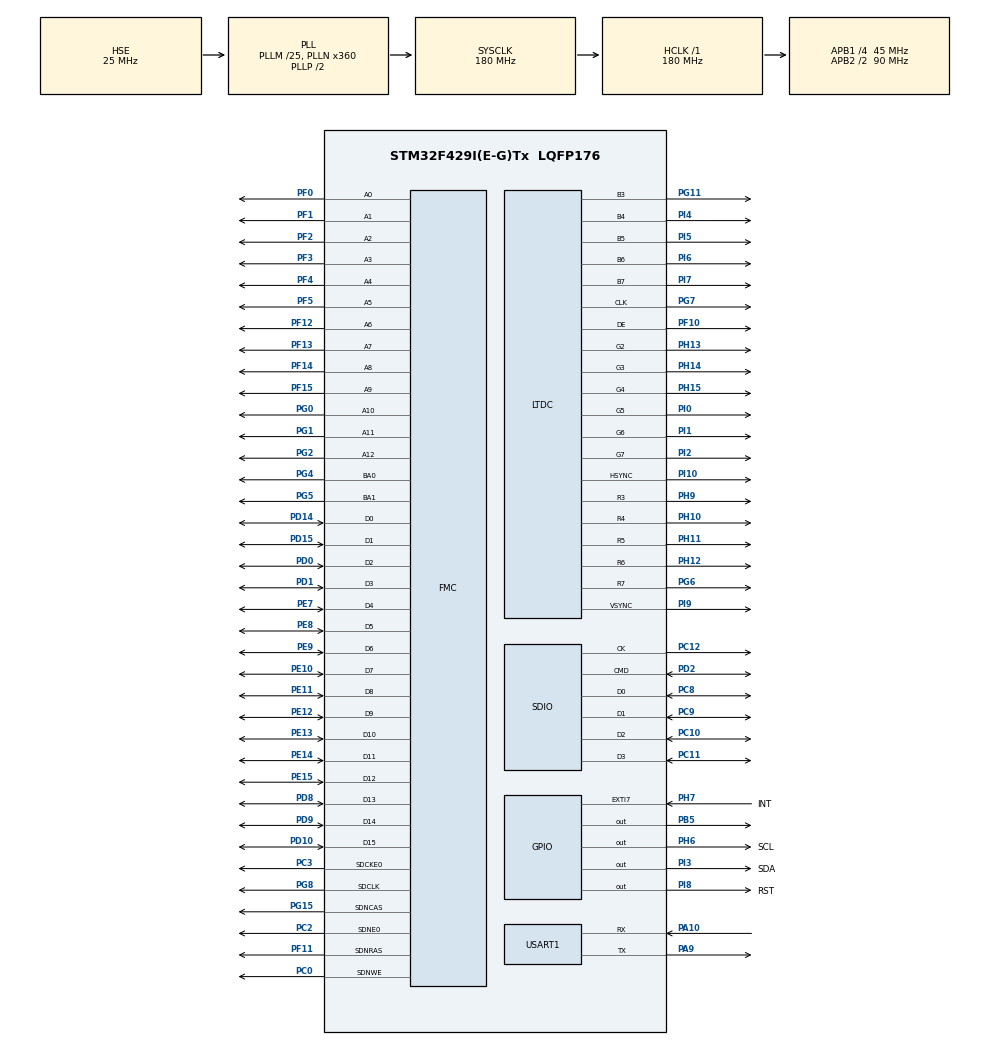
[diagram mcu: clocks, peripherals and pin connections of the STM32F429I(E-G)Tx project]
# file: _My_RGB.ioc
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DMA2D.ColorMode=DMA2D_OUTPUT_RGB565
Dma.Request0=SDIO_RX
Dma.Request1=SDIO_TX
Dma.SDIO_RX.0.Direction=DMA_PERIPH_TO_MEMORY
Dma.SDIO_RX.0.FIFOMode=DMA_FIFOMODE_ENABLE
Dma.SDIO_RX.0.FIFOThreshold=DMA_FIFO_THRESHOLD_FULL
Dma.SDIO_RX.0.Instance=DMA2_Stream3
Dma.SDIO_RX.0.MemBurst=DMA_MBURST_INC4
Dma.SDIO_RX.0.MemDataAlignment=DMA_MDATAALIGN_WORD
Dma.SDIO_RX.0.MemInc=DMA_MINC_ENABLE
Dma.SDIO_RX.0.Mode=DMA_PFCTRL
Dma.SDIO_RX.0.PeriphBurst=DMA_PBURST_INC4
Dma.SDIO_RX.0.PeriphDataAlignment=DMA_PDATAALIGN_WORD
Dma.SDIO_RX.0.PeriphInc=DMA_PINC_DISABLE
Dma.SDIO_RX.0.Priority=DMA_PRIORITY_LOW
Dma.SDIO_TX.1.Direction=DMA_MEMORY_TO_PERIPH
Dma.SDIO_TX.1.FIFOMode=DMA_FIFOMODE_ENABLE
Dma.SDIO_TX.1.FIFOThreshold=DMA_FIFO_THRESHOLD_FULL
Dma.SDIO_TX.1.Instance=DMA2_Stream6
Dma.SDIO_TX.1.MemBurst=DMA_MBURST_INC4
Dma.SDIO_TX.1.MemDataAlignment=DMA_MDATAALIGN_WORD
Dma.SDIO_TX.1.MemInc=DMA_MINC_ENABLE
Dma.SDIO_TX.1.Mode=DMA_PFCTRL
Dma.SDIO_TX.1.PeriphBurst=DMA_PBURST_INC4
Dma.SDIO_TX.1.PeriphDataAlignment=DMA_PDATAALIGN_WORD
Dma.SDIO_TX.1.PeriphInc=DMA_PINC_DISABLE
Dma.SDIO_TX.1.Priority=DMA_PRIORITY_LOW
FATFS._CODE_PAGE=936
FATFS._USE_LFN=2
FMC.CASLatency1=FMC_SDRAM_CAS_LATENCY_3
FMC.ColumnBitsNumber1=FMC_SDRAM_COLUMN_BITS_NUM_9
FMC.ExitSelfRefreshDelay1=8
FMC.LoadToActiveDelay1=2
FMC.RCDDelay1=2
FMC.RPDelay1=2
FMC.ReadPipeDelay1=FMC_SDRAM_RPIPE_DELAY_1
FMC.RowCycleDelay1=6
FMC.SDClockPeriod1=FMC_SDRAM_CLOCK_PERIOD_2
FMC.SelfRefreshTime1=6
FMC.WriteRecoveryTime1=4
LTDC.ActiveW=800
LTDC.Alpha_L0=255
LTDC.FBStartAdress_L0=0xC0000000
LTDC.FBStartAdress_L1=0xC0200000
LTDC.HBP=88
LTDC.HFP=40
LTDC.HSync=48
LTDC.ImageHeight_L0=480
LTDC.ImageHeight_L1=480
LTDC.ImageWidth_L0=800
LTDC.ImageWidth_L1=800
LTDC.PixelFormat_L0=LTDC_PIXEL_FORMAT_RGB565
LTDC.PixelFormat_L1=LTDC_PIXEL_FORMAT_RGB565
LTDC.VBP=32
LTDC.VFP=13
LTDC.VSPolarity=LTDC_VSPOLARITY_AL
LTDC.VSync=3
LTDC.WindowX1_L0=800
LTDC.WindowX1_L1=800
LTDC.WindowY1_L0=480
LTDC.WindowY1_L1=480
Mcu.Family=STM32F4
Mcu.Name=STM32F429I(E-G)Tx
Mcu.Package=LQFP176
NVIC.DMA2_Stream3_IRQn=true\:3\:3\:true\:false\:true\:false\:true
NVIC.DMA2_Stream6_IRQn=true\:3\:3\:true\:false\:true\:false\:true
NVIC.EXTI9_5_IRQn=true\:1\:1\:true\:false\:true\:true\:true
NVIC.PriorityGroup=NVIC_PRIORITYGROUP_2
NVIC.SDIO_IRQn=true\:0\:0\:false\:false\:true\:true\:true
NVIC.USART1_IRQn=true\:1\:1\:true\:false\:true\:true\:true
PA10.Mode=Asynchronous
PA10.Signal=USART1_RX
PA9.Mode=Asynchronous
PA9.Signal=USART1_TX
PB5.GPIO_PuPd=GPIO_PULLUP
PB5.GPIO_Speed=GPIO_SPEED_FREQ_VERY_HIGH
PB5.PinState=GPIO_PIN_SET
PB5.Signal=GPIO_Output
PC0.GPIO_PuPd=GPIO_PULLUP
PC0.Signal=FMC_SDNWE
PC10.Mode=SD_4_bits_Wide_bus
PC10.Signal=SDIO_D2
PC11.Mode=SD_4_bits_Wide_bus
PC11.Signal=SDIO_D3
PC12.Mode=SD_4_bits_Wide_bus
PC12.Signal=SDIO_CK
PC2.GPIO_PuPd=GPIO_PULLUP
PC2.Mode=SdramChipSelect1_1
PC2.Signal=FMC_SDNE0
PC3.GPIO_PuPd=GPIO_PULLUP
PC3.Mode=SdramChipSelect1_1
PC3.Signal=FMC_SDCKE0
PC8.Mode=SD_4_bits_Wide_bus
PC8.Signal=SDIO_D0
PC9.Mode=SD_4_bits_Wide_bus
PC9.Signal=SDIO_D1
PD0.GPIO_PuPd=GPIO_PULLUP
PD0.Signal=FMC_D2_DA2
PD1.GPIO_PuPd=GPIO_PULLUP
PD1.Signal=FMC_D3_DA3
PD10.GPIO_PuPd=GPIO_PULLUP
PD10.Signal=FMC_D15_DA15
PD14.GPIO_PuPd=GPIO_PULLUP
PD14.Signal=FMC_D0_DA0
PD15.GPIO_PuPd=GPIO_PULLUP
PD15.Signal=FMC_D1_DA1
PD2.Mode=SD_4_bits_Wide_bus
PD2.Signal=SDIO_CMD
PD8.GPIO_PuPd=GPIO_PULLUP
PD8.Signal=FMC_D13_DA13
PD9.GPIO_PuPd=GPIO_PULLUP
PD9.Signal=FMC_D14_DA14
PE0.Signal=FMC_NBL0
PE1.Signal=FMC_NBL1
PE10.GPIO_PuPd=GPIO_PULLUP
PE10.Signal=FMC_D7_DA7
PE11.GPIO_PuPd=GPIO_PULLUP
PE11.Signal=FMC_D8_DA8
PE12.GPIO_PuPd=GPIO_PULLUP
PE12.Signal=FMC_D9_DA9
PE13.GPIO_PuPd=GPIO_PULLUP
PE13.Signal=FMC_D10_DA10
PE14.GPIO_PuPd=GPIO_PULLUP
PE14.Signal=FMC_D11_DA11
PE15.GPIO_PuPd=GPIO_PULLUP
PE15.Signal=FMC_D12_DA12
PE7.GPIO_PuPd=GPIO_PULLUP
PE7.Signal=FMC_D4_DA4
PE8.GPIO_PuPd=GPIO_PULLUP
PE8.Signal=FMC_D5_DA5
PE9.GPIO_PuPd=GPIO_PULLUP
PE9.Signal=FMC_D6_DA6
PF0.GPIO_PuPd=GPIO_PULLUP
PF0.Signal=FMC_A0
PF1.GPIO_PuPd=GPIO_PULLUP
PF1.Signal=FMC_A1
PF10.GPIO_Speed=GPIO_SPEED_FREQ_VERY_HIGH
PF10.Mode=RGB565
PF10.Signal=LTDC_DE
PF11.GPIO_PuPd=GPIO_PULLUP
PF11.Signal=FMC_SDNRAS
PF12.GPIO_PuPd=GPIO_PULLUP
PF12.Signal=FMC_A6
PF13.GPIO_PuPd=GPIO_PULLUP
PF13.Signal=FMC_A7
PF14.GPIO_PuPd=GPIO_PULLUP
PF14.Signal=FMC_A8
PF15.GPIO_PuPd=GPIO_PULLUP
PF15.Signal=FMC_A9
PF2.GPIO_PuPd=GPIO_PULLUP
PF2.Signal=FMC_A2
PF3.GPIO_PuPd=GPIO_PULLUP
PF3.Signal=FMC_A3
PF4.GPIO_PuPd=GPIO_PULLUP
PF4.Signal=FMC_A4
PF5.GPIO_PuPd=GPIO_PULLUP
PF5.Signal=FMC_A5
PG0.GPIO_PuPd=GPIO_PULLUP
PG0.Signal=FMC_A10
PG1.GPIO_PuPd=GPIO_PULLUP
PG1.Signal=FMC_A11
PG11.GPIO_Speed=GPIO_SPEED_FREQ_VERY_HIGH
PG11.Mode=RGB565
PG11.Signal=LTDC_B3
PG15.GPIO_PuPd=GPIO_PULLUP
PG15.Signal=FMC_SDNCAS
PG2.GPIO_PuPd=GPIO_PULLUP
PG2.Signal=FMC_A12
PG4.GPIO_PuPd=GPIO_PULLUP
PG4.Signal=FMC_A14_BA0
PG5.GPIO_PuPd=GPIO_PULLUP
PG5.Signal=FMC_A15_BA1
PG6.GPIO_Speed=GPIO_SPEED_FREQ_VERY_HIGH
PG6.Mode=RGB565
PG6.Signal=LTDC_R7
PG7.GPIO_Speed=GPIO_SPEED_FREQ_VERY_HIGH
PG7.Mode=RGB565
PG7.Signal=LTDC_CLK
PG8.GPIO_PuPd=GPIO_PULLUP
PG8.Signal=FMC_SDCLK
PH0/OSC_IN.Mode=HSE-External-Oscillator
PH0/OSC_IN.Signal=RCC_OSC_IN
PH1/OSC_OUT.Mode=HSE-External-Oscillator
PH1/OSC_OUT.Signal=RCC_OSC_OUT
PH10.GPIO_Speed=GPIO_SPEED_FREQ_VERY_HIGH
PH10.Mode=RGB565
PH10.Signal=LTDC_R4
PH11.GPIO_Speed=GPIO_SPEED_FREQ_VERY_HIGH
PH11.Mode=RGB565
PH11.Signal=LTDC_R5
PH12.GPIO_Speed=GPIO_SPEED_FREQ_VERY_HIGH
PH12.Mode=RGB565
PH12.Signal=LTDC_R6
PH13.GPIO_Speed=GPIO_SPEED_FREQ_VERY_HIGH
PH13.Mode=RGB565
PH13.Signal=LTDC_G2
PH14.GPIO_Speed=GPIO_SPEED_FREQ_VERY_HIGH
PH14.Mode=RGB565
PH14.Signal=LTDC_G3
PH15.GPIO_Speed=GPIO_SPEED_FREQ_VERY_HIGH
PH15.Mode=RGB565
PH15.Signal=LTDC_G4
PH6.GPIO_Label=SCL
PH6.GPIO_Speed=GPIO_SPEED_FREQ_VERY_HIGH
PH6.Signal=GPIO_Output
PH7.GPIO_Label=INT
PH7.GPIO_ModeDefaultEXTI=GPIO_MODE_IT_FALLING
PH7.GPIO_PuPd=GPIO_PULLUP
PH7.Signal=GPXTI7
PH9.GPIO_Speed=GPIO_SPEED_FREQ_VERY_HIGH
PH9.Mode=RGB565
PH9.Signal=LTDC_R3
PI0.GPIO_Speed=GPIO_SPEED_FREQ_VERY_HIGH
PI0.Mode=RGB565
PI0.Signal=LTDC_G5
PI1.GPIO_Speed=GPIO_SPEED_FREQ_VERY_HIGH
PI1.Mode=RGB565
PI1.Signal=LTDC_G6
PI10.GPIO_Speed=GPIO_SPEED_FREQ_VERY_HIGH
PI10.Mode=RGB565
PI10.Signal=LTDC_HSYNC
PI2.GPIO_Speed=GPIO_SPEED_FREQ_VERY_HIGH
PI2.Mode=RGB565
PI2.Signal=LTDC_G7
PI3.GPIO_Label=SDA
PI3.GPIO_Speed=GPIO_SPEED_FREQ_VERY_HIGH
PI3.Signal=GPIO_Output
PI4.GPIO_Speed=GPIO_SPEED_FREQ_VERY_HIGH
PI4.Mode=RGB565
PI4.Signal=LTDC_B4
PI5.GPIO_Speed=GPIO_SPEED_FREQ_VERY_HIGH
PI5.Mode=RGB565
PI5.Signal=LTDC_B5
PI6.GPIO_Speed=GPIO_SPEED_FREQ_VERY_HIGH
PI6.Mode=RGB565
PI6.Signal=LTDC_B6
PI7.GPIO_Speed=GPIO_SPEED_FREQ_VERY_HIGH
PI7.Mode=RGB565
PI7.Signal=LTDC_B7
PI8.GPIO_Label=RST
PI8.Signal=GPIO_Output
PI9.GPIO_Speed=GPIO_SPEED_FREQ_VERY_HIGH
PI9.Mode=RGB565
PI9.Signal=LTDC_VSYNC
ProjectManager.HeapSize=0x1000
ProjectManager.StackSize=0x1000
ProjectManager.TargetToolchain=MDK-ARM V5.27
RCC.48MHZClocksFreq_Value=45000000
RCC.AHBFreq_Value=180000000
RCC.APB1CLKDivider=RCC_HCLK_DIV4
RCC.APB1Freq_Value=45000000
RCC.APB1TimFreq_Value=90000000
RCC.APB2CLKDivider=RCC_HCLK_DIV2
RCC.APB2Freq_Value=90000000
RCC.APB2TimFreq_Value=180000000
RCC.CortexFreq_Value=180000000
RCC.HCLKFreq_Value=180000000
RCC.HSE_VALUE=25000000
RCC.HSI_VALUE=16000000
RCC.LSE_VALUE=32768
RCC.PLLM=25
RCC.PLLN=360
RCC.PLLQ=8
RCC.PLLSAIN=152
RCC.PLLSourceVirtual=RCC_PLLSOURCE_HSE
RCC.SYSCLKFreq_VALUE=180000000
RCC.SYSCLKSource=RCC_SYSCLKSOURCE_PLLCLK
RCC.VCOOutputFreq_Value=360000000
SDIO.ClockDiv=4
SH.FMC_A0.0=FMC_A0,13b-sda1
SH.FMC_A1.0=FMC_A1,13b-sda1
SH.FMC_A10.0=FMC_A10,13b-sda1
SH.FMC_A11.0=FMC_A11,13b-sda1
SH.FMC_A12.0=FMC_A12,13b-sda1
SH.FMC_A14_BA0.0=FMC_BA0,FourSdramBanks1
SH.FMC_A15_BA1.0=FMC_BA1,FourSdramBanks1
SH.FMC_A2.0=FMC_A2,13b-sda1
SH.FMC_A3.0=FMC_A3,13b-sda1
SH.FMC_A4.0=FMC_A4,13b-sda1
SH.FMC_A5.0=FMC_A5,13b-sda1
SH.FMC_A6.0=FMC_A6,13b-sda1
SH.FMC_A7.0=FMC_A7,13b-sda1
SH.FMC_A8.0=FMC_A8,13b-sda1
SH.FMC_A9.0=FMC_A9,13b-sda1
SH.FMC_D0_DA0.0=FMC_D0,sd-16b-d1
SH.FMC_D10_DA10.0=FMC_D10,sd-16b-d1
SH.FMC_D11_DA11.0=FMC_D11,sd-16b-d1
SH.FMC_D12_DA12.0=FMC_D12,sd-16b-d1
SH.FMC_D13_DA13.0=FMC_D13,sd-16b-d1
SH.FMC_D14_DA14.0=FMC_D14,sd-16b-d1
SH.FMC_D15_DA15.0=FMC_D15,sd-16b-d1
SH.FMC_D1_DA1.0=FMC_D1,sd-16b-d1
SH.FMC_D2_DA2.0=FMC_D2,sd-16b-d1
SH.FMC_D3_DA3.0=FMC_D3,sd-16b-d1
SH.FMC_D4_DA4.0=FMC_D4,sd-16b-d1
SH.FMC_D5_DA5.0=FMC_D5,sd-16b-d1
SH.FMC_D6_DA6.0=FMC_D6,sd-16b-d1
SH.FMC_D7_DA7.0=FMC_D7,sd-16b-d1
SH.FMC_D8_DA8.0=FMC_D8,sd-16b-d1
SH.FMC_D9_DA9.0=FMC_D9,sd-16b-d1
SH.FMC_NBL0.0=FMC_NBL0
SH.FMC_NBL1.0=FMC_NBL1
SH.FMC_SDCLK.0=FMC_SDCLK,13b-sda1
SH.FMC_SDNCAS.0=FMC_SDNCAS,13b-sda1
SH.FMC_SDNRAS.0=FMC_SDNRAS,13b-sda1
SH.FMC_SDNWE.0=FMC_SDNWE,13b-sda1
USART1.VirtualMode=VM_ASYNC
VP_DMA2D_VS_DMA2D.Mode=DMA2D_Activate
VP_FATFS_VS_SDIO.Mode=SDIO
board=custom

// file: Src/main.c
/* USER CODE BEGIN Header */
/**
  ******************************************************************************
  * @file           : main.c
  * @brief          : Main program body
  ******************************************************************************
  * @attention
  *
  * <h2><center>&copy; Copyright (c) 2020 STMicroelectronics.
  * All rights reserved.</center></h2>
  *
  * This software component is licensed by ST under BSD 3-Clause license,
  * the "License"; You may not use this file except in compliance with the
  * License. You may obtain a copy of the License at:
  *                        opensource.org/licenses/BSD-3-Clause
  *
  ******************************************************************************
  */
/* USER CODE END Header */

#include "main.h"
#include "dma.h"
#include "dma2d.h"
#include "fatfs.h"
#include "ltdc.h"
#include "sdio.h"
#include "usart.h"
#include "gpio.h"
#include "fmc.h"

/* USER CODE BEGIN Includes */

#include "BSP_RGB_LCD.h"
#include "image.h"
#include "GUI_Paint.h"
#include "GT911.h"
#include "malloc.h"
#include "usmart.h"
#include "ff.h"
#include "ff_gen_drv.h"
#include "piclib.h"

/* USER CODE END Includes */

/* USER CODE BEGIN PTD */
extern GT911_Dev Dev_Now;

void HAL_GPIO_EXTI_Callback(uint16_t GPIO_Pin)
{
	if(GPIO_Pin == GPIO_PIN_7)
	{
		Dev_Now.Touch = 1;
	}
}
/* USER CODE END PTD */

void SystemClock_Config(void);

/* USER CODE BEGIN 0 */

//FATFS SDFatFs;  /* File system object for SD card logical drive */
//FIL MyFile;     /* File object */
//char SDPath[4]; /* SD card logical drive path */
//static uint8_t buffer[_MAX_SS]; /* a work buffer for the f_mkfs() */

uint16_t *picture = NULL;

/* USER CODE END 0 */

int main(void)
{
  /* USER CODE BEGIN 1 */

//  FRESULT res;                                          /* FatFs function common result code */
//  uint32_t byteswritten, bytesread;                     /* File write/read counts */
//  uint8_t wtext[] = "This is STM32 working with FatFs"; /* File write buffer */
//  uint8_t rtext[100];                                   /* File read buffer */
//	uint8_t buffer[512];

  /* USER CODE END 1 */

  /* MCU Configuration--------------------------------------------------------*/

  /* Reset of all peripherals, Initializes the Flash interface and the Systick. */
  HAL_Init();

  /* Configure the system clock */
  SystemClock_Config();

  /* Initialize all configured peripherals */
  MX_GPIO_Init();
  MX_LTDC_Init();
  MX_FMC_Init();
  MX_DMA2D_Init();
  MX_USART1_UART_Init();
  MX_DMA_Init();
  MX_SDIO_SD_Init();
//  MX_FATFS_Init();
  /* USER CODE BEGIN 2 */

	/*LCD初始化*/
	BSP_LCD_Init();

	/*打开背光*/
	HAL_GPIO_WritePin(GPIOB,GPIO_PIN_5,GPIO_PIN_SET);

/*malloc.c中初始化内存池*/
	my_mem_init(SRAMIN);		    //初始化内部内存池
	my_mem_init(SRAMEX);		    //初始化外部内存池
	my_mem_init(SRAMCCM);		    //初始化CCM内存池

/*USMART调试工具初始化*/
	usmart_dev.init(90);

	/*使能串口1接受中断*/
	__HAL_UART_ENABLE_IT(&huart1,UART_IT_RXNE);

	/*为fatfs相关变量申请内存	*/
	exfuns_init();

	/*FATFS文件系统初始化，初始化SD卡并挂载SD卡*/
	if(FATFS_LinkDriver(&SD_Driver, SDPath) == 0)
		{
			/*##-2- Register the file system object to the FatFs module ##############*/
			if(f_mount(&SDFatFS, (TCHAR const*)SDPath, 0) != FR_OK)
			{
				/* FatFs Initialization Error */
				Error_Handler();
				Debug("挂载失败\r\n");
			}
			else
			{
				/*##-3- Create a FAT file system (format) on the logical drive #########*/
				/* WARNING: Formatting the uSD card will delete all content on the device */
				if(disk_initialize(0) != 0)//在这一步进行了SD卡初始化   f_mkfs((TCHAR const*)SDPath, FM_ANY, 0, buffer, sizeof(buffer)) != FR_OK  disk_initialize(0) != 0
				{
					/* FatFs Format Error */
					Error_Handler();
					Debug("SD卡初始化失败\r\n");
				}
				else
				{
					/*##-4- Create and Open a new text file object with write access #####*/
//					if(f_open(&SDFile, "STM32.TXT", FA_CREATE_ALWAYS | FA_WRITE) != FR_OK)
//					{
//						/* 'STM32.TXT' file Open for write Error */
//						Error_Handler();
//						Debug("创建文件失败\r\n");
//					}
//					else
//					{
//						/*##-5- Write data to the text file ################################*/
//						res = f_write(&SDFile, wtext, sizeof(wtext), (void *)&byteswritten);

//						/*##-6- Close the open text file #################################*/
//						if (f_close(&SDFile) != FR_OK )
//						{
//							Error_Handler();
//							Debug("关闭文件失败\r\n");
//						}
//
//						if((byteswritten == 0) || (res != FR_OK))
//						{
//							/* 'STM32.TXT' file Write or EOF Error */
//							Error_Handler();
//							Debug("写文件信息失败\r\n");
//						}
//						else
//						{
//							/*##-7- Open the text file object with read access ###############*/
//							if(f_open(&SDFile, "STM32.TXT", FA_READ) != FR_OK)
//							{
//								/* 'STM32.TXT' file Open for read Error */
//								Error_Handler();
//								Debug("文件打开失败\r\n");
//							}
//							else
//							{
//								/*##-8- Read data from the text file ###########################*/
//								res = f_read(&SDFile, rtext, sizeof(rtext), (UINT*)&bytesread);
//
//								if((bytesread == 0) || (res != FR_OK))
//								{
//									/* 'STM32.TXT' file Read or EOF Error */
//									Error_Handler();
//									Debug("文件读取失败或EOF错误\r\n");
//								}
//								else
//								{
//									/*##-9- Close the open text file #############################*/
//									f_close(&SDFile);
//
//									/*##-10- Compare read data with the expected data ############*/
//									if((bytesread != byteswritten))
//									{
//										/* Read data is different from the expected data */
//										Error_Handler();
//										Debug("读数据不同\r\n");
//									}
//									else
//									{
										/* Success of the demo: no error occurrence */
										Debug("SD卡挂载并写入成功\r\n");
//									}
//								}
//							}
//						}
//					}
				}
			}
		}
		else
		{
			/* Read data is different from the expected data */
			Error_Handler();
			Debug("FATFS文件系统链接失败r\n");
		}

	/*刷屏代码*/
	Paint_NewImage(LCD_WIDTH, LCD_HEIGHT, ROTATE_0, WHITE);
	Paint_Clear(WHITE);
	Paint_DrawString_EN(10, 230, "1234567890", &Font24, 0x000f, 0xfff0);
	Paint_DrawString_EN(10, 260, "ABCDEFGHIJ", &Font24, BLUE, CYAN);
	Paint_DrawString_CN(10, 290, "微雪电子", &Font24CN, BLUE, CYAN);

	Paint_DrawRectangle(200, 230, 300, 330, RED,DRAW_FILL_EMPTY, DOT_PIXEL_2X2 );
	Paint_DrawLine(200, 230, 300, 330, MAGENTA, LINE_STYLE_SOLID, DOT_PIXEL_2X2);
	Paint_DrawLine(300, 230, 200, 330, MAGENTA, LINE_STYLE_SOLID, DOT_PIXEL_2X2);
	Paint_DrawCircle(250, 280, 45, GREEN, DRAW_FILL_EMPTY, DOT_PIXEL_2X2);
	Paint_DrawImage(gImage_800X221, 0, 0, 800, 221);
	Paint_DrawString_EN(715, 0, "clear", &Font24, BLUE, CYAN);/*每个字符占17个x坐标 24个Y坐标*/

	/*GT9147触摸IC初始化*/
	GT911_Init();

	/*解码图片*/
//	if(f_open(&SDFile, "image.jpg", FA_READ) == FR_OK)
//	{
//		/* Decode the jpg image file */
//		Debug("文件打开成功\r\n");
//		jpeg_decode(&SDFile, 800, _aucLine, Jpeg_CallbackFunction);
		picture = (uint16_t*)mymalloc(SRAMEX,800*480*2);
		piclib_init();										//初始化画图
		ai_load_picfile((const u8*)"0:/image2.jpg",0,0,800,480,1);//显示图片

//		Paint_DrawImage((const unsigned char*)picture, 0, 0, 800, 480);

		myfree(SRAMEX,picture);
		/* Close the JPG image */
//		f_close(&SDFile);
//	}
//	else
//	{
//		Debug("文件打开失败\r\n");
//	}
  /* USER CODE END 2 */

  /* Infinite loop */
  /* USER CODE BEGIN WHILE */
  while (1)
  {

		ctp_test();
    /* USER CODE END WHILE */

  }
}

void SystemClock_Config(void)
{
  RCC_OscInitTypeDef RCC_OscInitStruct = {0};
  RCC_ClkInitTypeDef RCC_ClkInitStruct = {0};
  RCC_PeriphCLKInitTypeDef PeriphClkInitStruct = {0};

  /** Configure the main internal regulator output voltage
  */
  __HAL_RCC_PWR_CLK_ENABLE();
  __HAL_PWR_VOLTAGESCALING_CONFIG(PWR_REGULATOR_VOLTAGE_SCALE1);
  /** Initializes the CPU, AHB and APB busses clocks
  */
  RCC_OscInitStruct.OscillatorType = RCC_OSCILLATORTYPE_HSE;
  RCC_OscInitStruct.HSEState = RCC_HSE_ON;
  RCC_OscInitStruct.PLL.PLLState = RCC_PLL_ON;
  RCC_OscInitStruct.PLL.PLLSource = RCC_PLLSOURCE_HSE;
  RCC_OscInitStruct.PLL.PLLM = 25;
  RCC_OscInitStruct.PLL.PLLN = 360;
  RCC_OscInitStruct.PLL.PLLP = RCC_PLLP_DIV2;
  RCC_OscInitStruct.PLL.PLLQ = 8;
  if (HAL_RCC_OscConfig(&RCC_OscInitStruct) != HAL_OK)
  {
    Error_Handler();
  }
  /** Activate the Over-Drive mode
  */
  if (HAL_PWREx_EnableOverDrive() != HAL_OK)
  {
    Error_Handler();
  }
  /** Initializes the CPU, AHB and APB busses clocks
  */
  RCC_ClkInitStruct.ClockType = RCC_CLOCKTYPE_HCLK|RCC_CLOCKTYPE_SYSCLK
                              |RCC_CLOCKTYPE_PCLK1|RCC_CLOCKTYPE_PCLK2;
  RCC_ClkInitStruct.SYSCLKSource = RCC_SYSCLKSOURCE_PLLCLK;
  RCC_ClkInitStruct.AHBCLKDivider = RCC_SYSCLK_DIV1;
  RCC_ClkInitStruct.APB1CLKDivider = RCC_HCLK_DIV4;
  RCC_ClkInitStruct.APB2CLKDivider = RCC_HCLK_DIV2;

  if (HAL_RCC_ClockConfig(&RCC_ClkInitStruct, FLASH_LATENCY_5) != HAL_OK)
  {
    Error_Handler();
  }
  PeriphClkInitStruct.PeriphClockSelection = RCC_PERIPHCLK_LTDC;
  PeriphClkInitStruct.PLLSAI.PLLSAIN = 152;
  PeriphClkInitStruct.PLLSAI.PLLSAIR = 2;
  PeriphClkInitStruct.PLLSAIDivR = RCC_PLLSAIDIVR_2;
  if (HAL_RCCEx_PeriphCLKConfig(&PeriphClkInitStruct) != HAL_OK)
  {
    Error_Handler();
  }
}

void Error_Handler(void)
{
}

/************************ (C) COPYRIGHT STMicroelectronics *****END OF FILE****/
